# Polarfire SoC register map
Vendor: Microchip; File version: 1.0
CPU: Microchip PolarFire SoC 1.0, little endian
Registers are 32-bit, read-write, reset 0x0 unless marked. A register's access mark holds for its fields unless they carry their own. Offsets are from the block's base; [hi:lo] are bit positions; {n}, {i} and the like mark numbered series.

## I2C_A_LO — I2C_A_LO Controller
Base 0x2010A000
Same registers: I2C_B_LO 0x2010B000, I2C_A_HI 0x2810A000, I2C_B_HI 0x2810B000
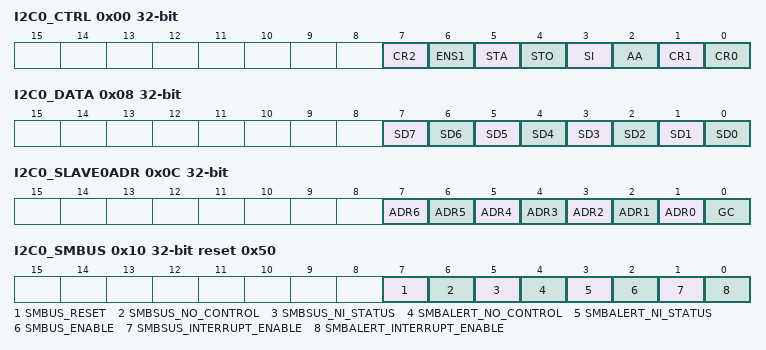
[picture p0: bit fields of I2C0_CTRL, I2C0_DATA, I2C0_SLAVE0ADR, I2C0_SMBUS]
0x00 I2C0_CTRL
  [7] CR2 — Clock rate bit 2; refer to bit 0.
  [6] ENS1 — Enable bit. When ens1='0', the sda and scl outputs are in a high impedance and sda and scl input signals are ignored. When ens1='1', the Core is enabled
  [5] STA — The START Flag. When sta='1', the Core checks the status of the serial bus and generates a START condition if the bus is free.
  [4] STO — The STOP Flag. When sto='1' and the Core is in a master mode, a STOP condition is transmitted to the serial bus.
  [3] SI — The Serial Interrupt Flag. The SI flag is set by the Core whenever there is a service-able change in the Status Register. After the register has been updated, the "si" bit must be cleared by software. NOTE: The si bit is directly readable via the APB INTERRUPT signal.
  [2] AA — The Assert Acknowledge Flag. When aa='1' an acknowledge will be returned when: The "own slave address" has been received. The general call address has been received while the gc bit in the Address register is set . A data byte has been received while the Core is in the master receiver mode . A data byte has been received while the Core is in the slave receiver mode. When aa='0', a not acknowledge will be returned when: A data byte has been received while the Core is in the master receiver mode .A data byte has been received while F2DSS_I2C is in the slave receiver mode
  [1] CR1 — Serial Clock rate bit 1; refer to bit 0.
  [0] CR0 — Serial Clock rate bit 0 ; Clock Rate is defined as follows: 000: PCLK frequency/256, 001: PCLK frequency/224, 010:PCLK frequency/192, 011: PCLK frequency/160, 100: PCLK frequency/960, 101: PCLK frequency/120, 110: PCLK frequency/60, 111:BCLK frequency/8. Note: BCLK is synchronized to PCLK and hence must be PCLKFREQ/2 or less.
0x04 I2C0_STATUS ro reset 0xF8 — 1. Master Transmitter Mode, 2. Master Receiver Mode, 3. Slave Transmitter Mode, 4. Slave Receiver Mode.
  [7:0] STATUS_REGISTER — Read-only value yields the current state of the I2C Status Registers dependent on Mode. Master Transmitter Mode: 08H: A START condition has been transmitted. 10H: A repeated START condition has been transmitted 18H: SLA+W has been transmitted; ACK has been received 20H: SLA+W has been transmitted; not ACK has been received. 28H: Data byte in Data Register has been transmitted; ACK has been received. 30H: Data byte in Data Register has been transmitted; NACK has been received. 38H: Arbitration lost in SLA+R/W or data bytes. D0H: SMBus Master Reset has been activated. Master Receiver Mode: 08H: A START condition has been transmitted 10H: A repeated START condition has been transmitted 38H: Arbitration lost in not ACK bit 40H: SLA+R has been transmitted; ACK has been received 48H: SLA+R has been transmitted; not ACK has been received 50H: Data byte has been received; ACK has been returned 58H: Data byte has been received; not ACK has been returned D0H: SMBus Master Reset has been activated Slave Receiver Mode: 60H: Own SLA+W has been received; ACK has been returned 68H: Arbitration lost in SLA+R/W as master; own SLA+W has been received, ACK returned 70H: General call address (00H) has been received; ACK has been returned 78H: Arbitration lost in SLA+R/W as master; general call address has been received, ACK returned 80H: Previously addressed with own SLV address; DATA has been received; ACK returned 88H: Previously addressed with own SLA; DATA byte has been received; not ACK returned 90H: Previously addressed with general call address; DATA has been received; ACK returned 98H: Previously addressed with general call address; DATA has been received; NACK returned A0H: A STOP condition or repeated START condition has been received while still addressed as SLV/REC or SLV/TRX D8H: 25 ms SCL low time has been reached; device must be reset Slave Transmitter Mode: A8H: Own SLA+R has been received; ACK has been returned B0H: Arbitration lost in SLA+R/W as master; own SLA+R has been received; ACK has been returned B8H: Data byte has been transmitted; ACK has been received C0H: Data byte has been transmitted; not ACK has been received C8H: Last data byte has transmitted; ACK has received D8H: 25 ms SCL low time has been reached; device must be reset Miscellaneous States: 38H: Arbitration lost F8H: No relevant state information available; si=0 00H: Bus error during MST or selected slave modes
0x08 I2C0_DATA
  [7] SD7 — Serial data bit 7 (MSB), Serial address bit 6 (MSB)
  [6] SD6 — Serial data bit 6, Serial address bit 5
  [5] SD5 — Serial data bit 5, Serial address bit 4
  [4] SD4 — Serial data bit 4, Serial address bit 3.
  [3] SD3 — Serial data bit 3, Serial address bit 2
  [2] SD2 — Serial data bit 2, Serial address bit 1.
  [1] SD1 — Serial data bit 1, Serial address bit 0 (LSB)
  [0] SD0 — Serial data bit 0 (LSB). Direction Bit: '0' = Write; '1' = Read
0x0C I2C0_SLAVE0ADR
  [n+1] ADR{n} (n=0..6) — Own slave0 address bit {n}
  [0] GC — General Call Address Acknowledge. If the gc bit is set, the general call address is recognized; otherwise it is ignored.
0x10 I2C0_SMBUS reset 0x50
  [7] SMBUS_RESET — Writing a one to this bit will force the clock line low until 35 ms has been exceeded, thus resetting the entire bus as per the SMBus Specification Version 2.0
  [6] SMBSUS_NO_CONTROL — SMBSUS_NO control; used in master/host mode to force other devices into power down / suspend mode. Active low.
  [5] SMBSUS_NI_STATUS ro — Status of SMBSUS_NI signal.
  [4] SMBALERT_NO_CONTROL — SMBALERT_NO control; used in slave/device mode to force communication with the master/host. Wired-AND.
  [3] SMBALERT_NI_STATUS ro — Status of SMBALERT_NI signal. Wired-AND.
  [2] SMBUS_ENABLE — 0: SMBus timeouts and status logic disabled, i.e., standard I2C bus operation; 1: SMBus timeouts and status logic enabled
  [1] SMBSUS_INTERRUPT_ENABLE — 0: SMBSUS Interrupt signal (SMBS) disabled. 1: SMBSUS Interrupt signal (SMBS) enabled.
  [0] SMBALERT_INTERRUPT_ENABLE — 0: SMBALERT Interrupt signal (SMBA) disabled. 1: SMBALERT Interrupt signal (SMBA) enabled.
0x14 I2C0_FREQ reset 0x8
  [7:0] FREQUENCY — PCLK Frequency in Mhz, from 1 to 255. Necessary for configuring Real-time Timeout Logic. Can be set to the PCLK Frequency for 25 ms SMBus timeouts, or may be changed to increase/decrease the timeout value.
0x18 I2C0_GLITCHREG reset 0x3
  [7:0] GLITCHREG_NUM — This read/write register is used to adjust the input glitch filter length. Depending on the application, the glitch filter may be used to suppress spikes between 3 and 21 PCLK cycles. If GlitchReg_Fixed=0, then this register can be set from a length of 3 to 21
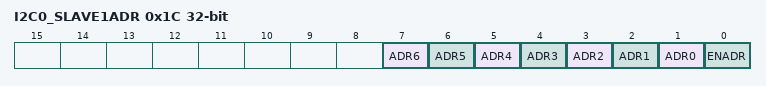
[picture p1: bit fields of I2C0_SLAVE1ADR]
0x1C I2C0_SLAVE1ADR
  [n+1] ADR{n} (n=0..6) — Own slave1 address bit {n}
  [0] ENADR — 1: Enable the SLAVE1 Address comparisons. 0: Disable SLAVE1 Address comparisons.
